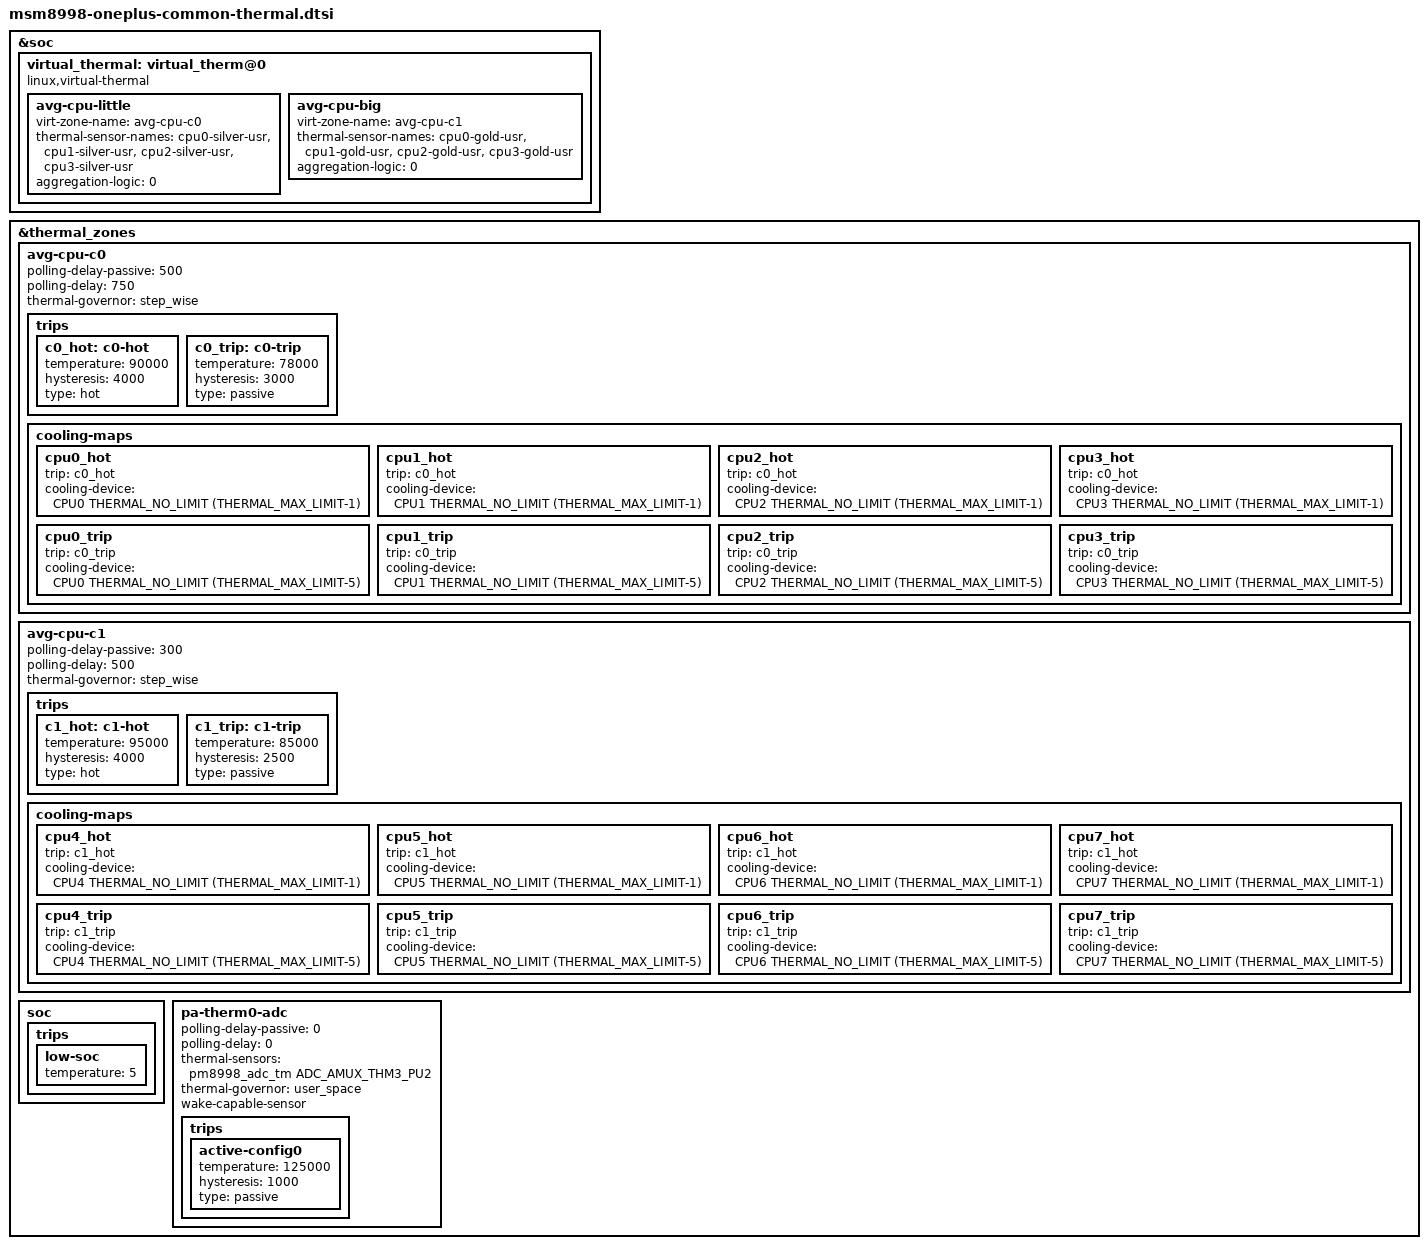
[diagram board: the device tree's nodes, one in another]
/* arch/arm64/boot/dts/qcom/msm8998-oneplus-common-thermal.dtsi
 *
 * This program is free software; you can redistribute it and/or modify
 * it under the terms of the GNU General Public License version 2 and
 * only version 2 as published by the Free Software Foundation.
 *
 * This program is distributed in the hope that it will be useful,
 * but WITHOUT ANY WARRANTY; without even the implied warranty of
 * MERCHANTABILITY or FITNESS FOR A PARTICULAR PURPOSE.  See the
 * GNU General Public License for more details.
 */
/*
 * Copyright (C) 2018 AngeloGioacchino Del Regno <kholk11@gmail.com>
 *
 * This program is free software; you can redistribute it and/or modify
 * it under the terms of the GNU General Public License version 2, as
 * published by the Free Software Foundation.
 */

&soc {
	virtual_thermal: virtual_therm@0 {
		compatible = "linux,virtual-thermal";
		status = "ok";
	};
};

&virtual_thermal {
	avg-cpu-little {
		virt-zone-name = "avg-cpu-c0";
		thermal-sensor-names = "cpu0-silver-usr", "cpu1-silver-usr",
				  "cpu2-silver-usr", "cpu3-silver-usr";
		aggregation-logic = <0>; /* WEIGHTED_AVG */
	};
	avg-cpu-big {
		virt-zone-name = "avg-cpu-c1";
		thermal-sensor-names = "cpu0-gold-usr", "cpu1-gold-usr",
				  "cpu2-gold-usr", "cpu3-gold-usr";
		aggregation-logic = <0>; /* WEIGHTED_AVG */
	};
};

&thermal_zones {
	avg-cpu-c0 {
		polling-delay-passive = <500>;
		polling-delay = <750>;
		thermal-governor = "step_wise";
		trips {
			c0_hot: c0-hot {
				temperature = <90000>;
				hysteresis = <4000>;
				type = "hot";
			};

			/* Target avg temp limit at max load */
			c0_trip: c0-trip {
				temperature = <78000>;
				hysteresis = <3000>;
				type = "passive";
			};
		};

		cooling-maps {
			cpu0_hot {
				trip = <&c0_hot>;
				cooling-device =
					<&CPU0 THERMAL_NO_LIMIT
						(THERMAL_MAX_LIMIT-1)>;
			};
			cpu1_hot {
				trip = <&c0_hot>;
				cooling-device =
					<&CPU1 THERMAL_NO_LIMIT
						(THERMAL_MAX_LIMIT-1)>;
			};
			cpu2_hot {
				trip = <&c0_hot>;
				cooling-device =
					<&CPU2 THERMAL_NO_LIMIT
						(THERMAL_MAX_LIMIT-1)>;
			};
			cpu3_hot {
				trip = <&c0_hot>;
				cooling-device =
					<&CPU3 THERMAL_NO_LIMIT
						(THERMAL_MAX_LIMIT-1)>;
			};

			cpu0_trip {
				trip = <&c0_trip>;
				cooling-device =
					<&CPU0 THERMAL_NO_LIMIT
						(THERMAL_MAX_LIMIT-5)>;
			};
			cpu1_trip {
				trip = <&c0_trip>;
				cooling-device =
					<&CPU1 THERMAL_NO_LIMIT
						(THERMAL_MAX_LIMIT-5)>;
			};
			cpu2_trip {
				trip = <&c0_trip>;
				cooling-device =
					<&CPU2 THERMAL_NO_LIMIT
						(THERMAL_MAX_LIMIT-5)>;
			};
			cpu3_trip {
				trip = <&c0_trip>;
				cooling-device =
					<&CPU3 THERMAL_NO_LIMIT
						(THERMAL_MAX_LIMIT-5)>;
			};
		};
	};

	avg-cpu-c1 {
		polling-delay-passive = <300>;
		polling-delay = <500>;
		thermal-governor = "step_wise";
		trips {
			c1_hot: c1-hot {
				temperature = <95000>;
				hysteresis = <4000>;
				type = "hot";
			};

			/* Target avg temp limit at max load */
			c1_trip: c1-trip {
				temperature = <85000>;
				hysteresis = <2500>;
				type = "passive";
			};
		};

		cooling-maps {
			cpu4_hot {
				trip = <&c1_hot>;
				cooling-device =
					<&CPU4 THERMAL_NO_LIMIT
						(THERMAL_MAX_LIMIT-1)>;
			};
			cpu5_hot {
				trip = <&c1_hot>;
				cooling-device =
					<&CPU5 THERMAL_NO_LIMIT
						(THERMAL_MAX_LIMIT-1)>;
			};
			cpu6_hot {
				trip = <&c1_hot>;
				cooling-device =
					<&CPU6 THERMAL_NO_LIMIT
						(THERMAL_MAX_LIMIT-1)>;
			};
			cpu7_hot {
				trip = <&c1_hot>;
				cooling-device =
					<&CPU7 THERMAL_NO_LIMIT
						(THERMAL_MAX_LIMIT-1)>;
			};

			cpu4_trip {
				trip = <&c1_trip>;
				cooling-device =
					<&CPU4 THERMAL_NO_LIMIT
						(THERMAL_MAX_LIMIT-5)>;
			};
			cpu5_trip {
				trip = <&c1_trip>;
				cooling-device =
					<&CPU5 THERMAL_NO_LIMIT
						(THERMAL_MAX_LIMIT-5)>;
			};
			cpu6_trip {
				trip = <&c1_trip>;
				cooling-device =
					<&CPU6 THERMAL_NO_LIMIT
						(THERMAL_MAX_LIMIT-5)>;
			};
			cpu7_trip {
				trip = <&c1_trip>;
				cooling-device =
					<&CPU7 THERMAL_NO_LIMIT
						(THERMAL_MAX_LIMIT-5)>;
			};
		};
	};

	/* Configure BCL SOC threshold */
	soc {
		trips {
			low-soc {
				temperature = <5>;
			};
		};
	};

	pa-therm0-adc {
		polling-delay-passive = <0>;
		polling-delay = <0>;
		thermal-sensors = <&pm8998_adc_tm ADC_AMUX_THM3_PU2>;
		thermal-governor = "user_space";
		wake-capable-sensor;

		trips {
			active-config0 {
				temperature = <125000>;
				hysteresis = <1000>;
				type = "passive";
			};
		};
	};
};
